# wl_phy_rx_dfe_secure register map
Vendor: Texas Instruments
Peripheral module from a debugger description file (folder CC35X1E).
Registers are 32-bit, access per field, reset 0x4000000 unless marked. A register's access mark holds for its fields unless they carry their own. Offsets are as the file gives them; lines under a group give offsets from that group; [hi:lo] are bit positions; {n}, {i} and the like mark numbered series; 'fields as' and 'values as' point back to an identical list; <NAME> marks a mode.

## wl_phy_rx_dfe_secure
0x00 rx_resamp_config_1
  [26:0] MEM_RX_RESAMP_DELTA_PHASE rw
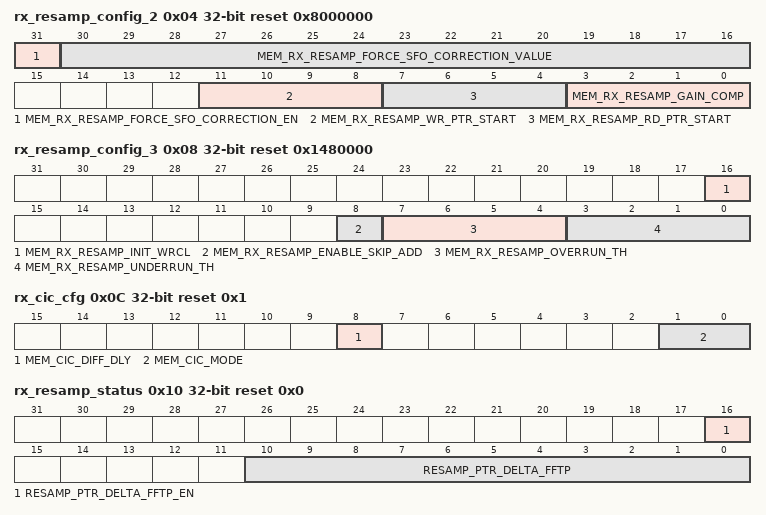
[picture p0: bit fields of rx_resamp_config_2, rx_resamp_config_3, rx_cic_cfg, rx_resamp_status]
0x04 rx_resamp_config_2 reset 0x8000000 (reset mask 0x7FFF0000)
  [31] MEM_RX_RESAMP_FORCE_SFO_CORRECTION_EN rw, [30:16] MEM_RX_RESAMP_FORCE_SFO_CORRECTION_VALUE rw, [11:8] MEM_RX_RESAMP_WR_PTR_START rw, [7:4] MEM_RX_RESAMP_RD_PTR_START rw, [3:0] MEM_RX_RESAMP_GAIN_COMP rw
0x08 rx_resamp_config_3 reset 0x1480000 (reset mask 0xFFFE0000)
  [16] MEM_RX_RESAMP_INIT_WRCL rw, [8] MEM_RX_RESAMP_ENABLE_SKIP_ADD rw, [7:4] MEM_RX_RESAMP_OVERRUN_TH rw, [3:0] MEM_RX_RESAMP_UNDERRUN_TH rw
0x0C rx_cic_cfg reset 0x1
  [8] MEM_CIC_DIFF_DLY rw
  [1:0] MEM_CIC_MODE rw — 0: Listen Mode, 1: Normal Mode, 2: Calibration Mode
0x10 rx_resamp_status ro reset 0x0
  [16] RESAMP_PTR_DELTA_FFTP_EN — 0: Listen Mode, 1: Normal Mode, 2: Calibration Mode
  [10:0] RESAMP_PTR_DELTA_FFTP — 0: Listen Mode, 1: Normal Mode, 2: Calibration Mode
